AUTOSAR XML (schema 00050)
package /Diag_DidSwc
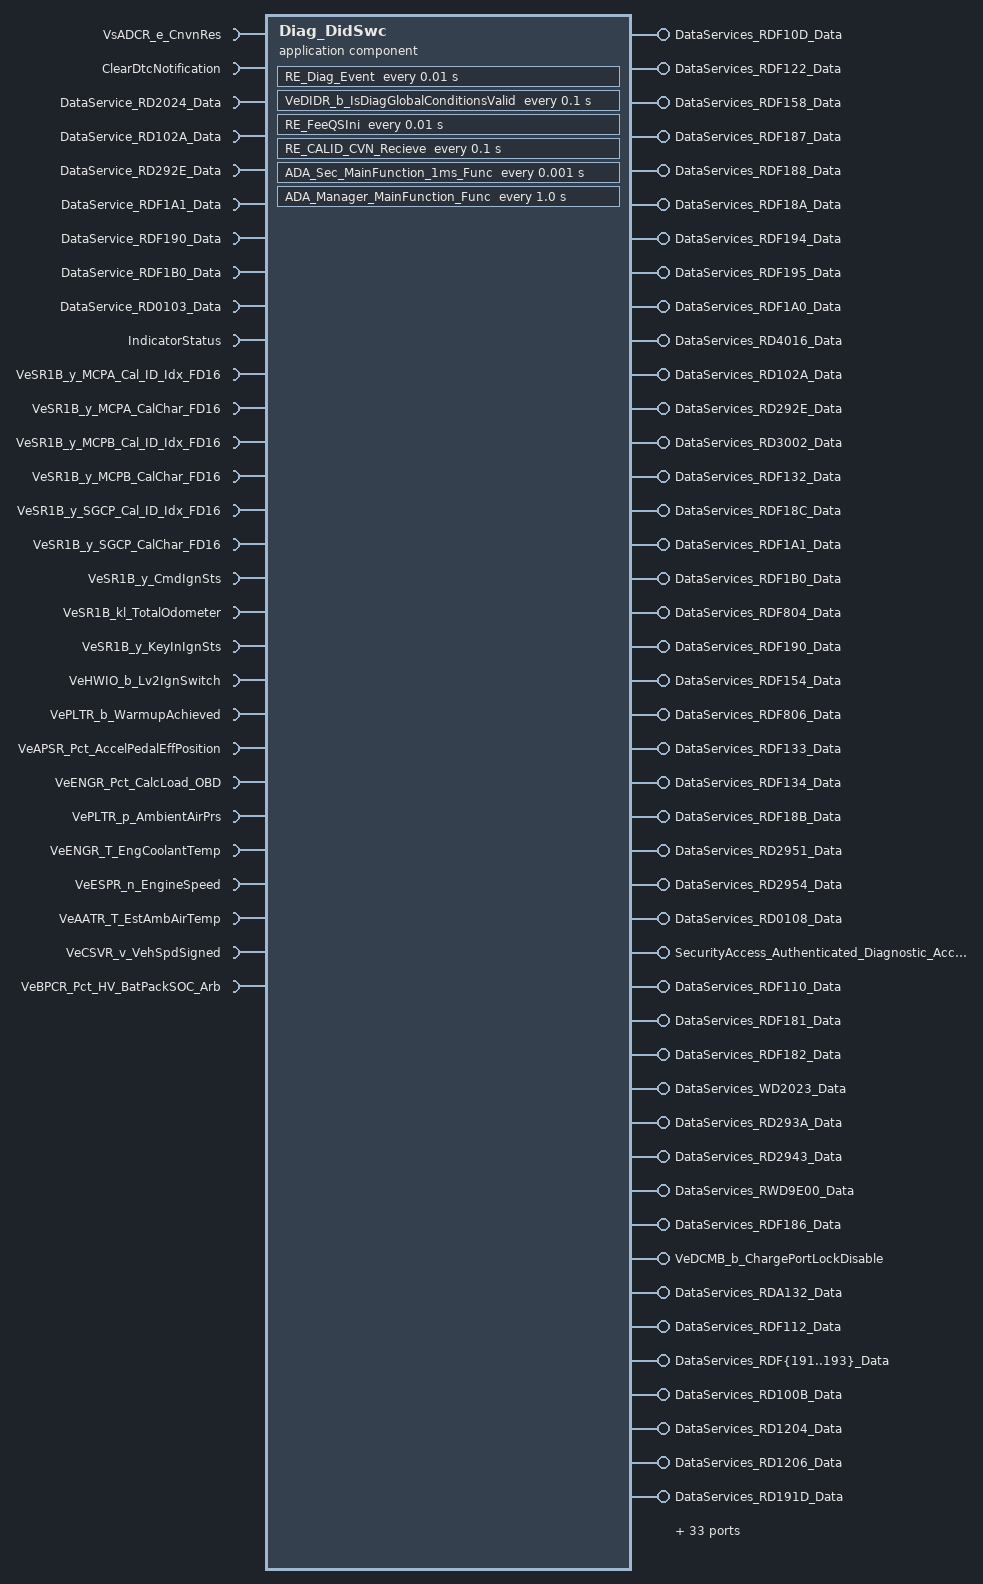
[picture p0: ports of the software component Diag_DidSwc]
  application sw component type Diag_DidSwc
    60 x provide port:
      DataServices_RDF10D_Data: provided-interface=DataServices_RDF10D_Data
      DataServices_RDF122_Data: provided-interface=DataServices_RDF122_Data
      DataServices_RDF158_Data: provided-interface=DataServices_RDF158_Data
      DataServices_RDF187_Data: provided-interface=DataServices_RDF187_Data
      DataServices_RDF188_Data: provided-interface=DataServices_RDF188_Data
      DataServices_RDF18A_Data: provided-interface=DataServices_RDF18A_Data
      DataServices_RDF194_Data: provided-interface=DataServices_RDF194_Data
      DataServices_RDF195_Data: provided-interface=DataServices_RDF195_Data
      DataServices_RDF1A0_Data: provided-interface=DataServices_RDF1A0_Data
      DataServices_RD4016_Data: provided-interface=DataServices_RD4016_Data
      DataServices_RD102A_Data: provided-interface=DataServices_RD102A_Data
      DataServices_RD292E_Data: provided-interface=DataServices_RD292E_Data
      DataServices_RD3002_Data: provided-interface=DataServices_RD3002_Data
      DataServices_RDF132_Data: provided-interface=DataServices_RDF132_Data
      DataServices_RDF18C_Data: provided-interface=DataServices_RDF18C_Data
      DataServices_RDF1A1_Data: provided-interface=DataServices_RDF1A1_Data
      DataServices_RDF1B0_Data: provided-interface=DataServices_RDF1B0_Data
      DataServices_RDF804_Data: provided-interface=DataServices_RDF804_Data
      DataServices_RDF190_Data: provided-interface=DataServices_RDF190_Data
      DataServices_RDF154_Data: provided-interface=DataServices_RDF154_Data
      DataServices_RDF806_Data: provided-interface=DataServices_RDF806_Data
      DataServices_RDF133_Data: provided-interface=DataServices_RDF133_Data
      DataServices_RDF134_Data: provided-interface=DataServices_RDF134_Data
      DataServices_RDF18B_Data: provided-interface=DataServices_RDF18B_Data
      DataServices_RD2951_Data: provided-interface=DataServices_RD2951_Data
      DataServices_RD2954_Data: provided-interface=DataServices_RD2954_Data
      DataServices_RD0108_Data: provided-interface=DataServices_RD0108_Data
      SecurityAccess_Authenticated_Diagnostic_Access_SecurityAccess_Even: provided-interface=SecurityAccess_Authenticated_Diagnostic_Access_SecurityAccess_Even
      DataServices_RDF110_Data: provided-interface=DataServices_RDF110_Data
      DataServices_RDF181_Data: provided-interface=DataServices_RDF181_Data
      DataServices_RDF182_Data: provided-interface=DataServices_RDF182_Data
      DataServices_WD2023_Data: provided-interface=DataServices_WD2023_Data
      DataServices_RD293A_Data: provided-interface=DataServices_RD293A_Data
      DataServices_RD2943_Data: provided-interface=DataServices_RD2943_Data
      DataServices_RWD9E00_Data: provided-interface=DataServices_RWD9E00_Data
      DataServices_RDF186_Data: provided-interface=DataServices_RDF186_Data
      VeDCMB_b_ChargePortLockDisable: provided-interface=VeDCMB_b_ChargePortLockDisable
      DataServices_RDA132_Data: provided-interface=DataServices_RDA132_Data
      DataServices_RDF112_Data: provided-interface=DataServices_RDF112_Data
      DataServices_RDF{191..193}_Data: provided-interface=DataServices_RDF{191..193}_Data
      DataServices_RD100B_Data: provided-interface=DataServices_RD100B_Data
      DataServices_RD1204_Data: provided-interface=DataServices_RD1204_Data
      DataServices_RD1206_Data: provided-interface=DataServices_RD1206_Data
      DataServices_RD191D_Data: provided-interface=DataServices_RD191D_Data
      DataServices_RD1921_Data: provided-interface=DataServices_RD1921_Data
      DataServices_RD2001_Data: provided-interface=DataServices_RD2001_Data
      DataServices_RD200A_Data: provided-interface=DataServices_RD200A_Data
      DataServices_RD200B_Data: provided-interface=DataServices_RD200B_Data
      DataServices_RD200C_Data: provided-interface=DataServices_RD200C_Data
      DataServices_RD6360_Data: provided-interface=DataServices_RD6360_Data
      DataServices_RDA186_Data: provided-interface=DataServices_RDA186_Data
      DataServices_RDF10B_Data: provided-interface=DataServices_RDF10B_Data
      DataServices_RDF155_Data: provided-interface=DataServices_RDF155_Data
      DataServices_RDF196_Data: provided-interface=DataServices_RDF196_Data
      DataServices_RD0701_Data: provided-interface=DataServices_RD0701_Data
      DataServices_RD1006_Data: provided-interface=DataServices_RD1006_Data
      DataServices_RD1008_Data: provided-interface=DataServices_RD1008_Data
      DataServices_RWD2945_Data: provided-interface=DataServices_RWD2945_Data
    require port VsADCR_e_CnvnRes: required-interface=VsADCR_e_CnvnRes
    5 x provide port:
      DataServices_RD0103_Data: provided-interface=DataServices_RD0103_Data
      DataServices_RWD0107_Data: provided-interface=DataServices_RWD0107_Data
      DataServices_RD0700_Data: provided-interface=DataServices_RD0700_Data
      DataServices_RD2010_Data: provided-interface=DataServices_RD2010_Data
      VeDIDR_b_IsDiagGlobalConditionsValid: provided-interface=VeDIDR_b_IsDiagGlobalConditionsValid
    4 x require port:
      ClearDtcNotification: required-interface=ClearDtcNotification
      DataService_RD2024_Data: required-interface=DataService_RD2024_Data
      DataService_RD102A_Data: required-interface=DataService_RD102A_Data
      DataService_RD292E_Data: required-interface=DataService_RD292E_Data
    provide port DataService_RD2023_Data: provided-interface=DataService_RD2023_Data
    4 x require port:
      DataService_RDF1A1_Data: required-interface=DataService_RDF1A1_Data
      DataService_RDF190_Data: required-interface=DataService_RDF190_Data
      DataService_RDF1B0_Data: required-interface=DataService_RDF1B0_Data
      DataService_RD0103_Data: required-interface=DataService_RD0103_Data
    provide port DataServices_RD2024_Data: provided-interface=DataServices_RD2024_Data
    11 x require port:
      IndicatorStatus: required-interface=IndicatorStatus
      VeSR1B_y_MCPA_Cal_ID_Idx_FD16: nonqueued-receiver-com-spec{data-element=Value, handle-never-received=true, init-value=0}, required-interface=VeSR1B_y_MCPA_Cal_ID_Idx_FD16
      VeSR1B_y_MCPA_CalChar_FD16: nonqueued-receiver-com-spec{data-element=Value, handle-never-received=true, init-value=0}, required-interface=VeSR1B_y_MCPA_CalChar_FD16
      VeSR1B_y_MCPB_Cal_ID_Idx_FD16: nonqueued-receiver-com-spec{data-element=Value, handle-never-received=true, init-value=0}, required-interface=VeSR1B_y_MCPB_Cal_ID_Idx_FD16
      VeSR1B_y_MCPB_CalChar_FD16: nonqueued-receiver-com-spec{data-element=Value, handle-never-received=true, init-value=0}, required-interface=VeSR1B_y_MCPB_CalChar_FD16
      VeSR1B_y_SGCP_Cal_ID_Idx_FD16: nonqueued-receiver-com-spec{data-element=Value, handle-never-received=true, init-value=0}, required-interface=VeSR1B_y_SGCP_Cal_ID_Idx_FD16
      VeSR1B_y_SGCP_CalChar_FD16: nonqueued-receiver-com-spec{data-element=Value, handle-never-received=true, init-value=0}, required-interface=VeSR1B_y_SGCP_CalChar_FD16
      VeSR1B_y_CmdIgnSts: nonqueued-receiver-com-spec{data-element=Value, handle-never-received=true, init-value=0}, required-interface=VeSR1B_y_CmdIgnSts
      VeSR1B_kl_TotalOdometer: nonqueued-receiver-com-spec{data-element=Value, handle-never-received=true, init-value=0}, required-interface=VeSR1B_kl_TotalOdometer
      VeSR1B_y_KeyInIgnSts: nonqueued-receiver-com-spec{data-element=Value, handle-never-received=true, init-value=0}, required-interface=VeSR1B_y_KeyInIgnSts
      VeHWIO_b_Lv2IgnSwitch: required-interface=VeHWIO_b_Lv2IgnSwitch
    4 x provide port:
      DataServices_RD1009_Data: provided-interface=DataServices_RD1009_Data
      DataServices_RD1004_Data: provided-interface=DataServices_RD1004_Data
      VeDIDR_b_PostCodeClrDiagDsbl: provided-interface=VeDIDR_b_PostCodeClrDiagDsbl
      VeDIDR_b_ClearTrackingInfoService04: provided-interface=VeDIDR_b_ClearTrackingInfoService04
    9 x require port:
      VePLTR_b_WarmupAchieved: required-interface=VePLTR_b_WarmupAchieved
      VeAPSR_Pct_AccelPedalEffPosition: required-interface=VeAPSR_Pct_AccelPedalEffPosition
      VeENGR_Pct_CalcLoad_OBD: required-interface=VeENGR_Pct_CalcLoad_OBD
      VePLTR_p_AmbientAirPrs: required-interface=VePLTR_p_AmbientAirPrs
      VeENGR_T_EngCoolantTemp: required-interface=VeENGR_T_EngCoolantTemp
      VeESPR_n_EngineSpeed: required-interface=VeESPR_n_EngineSpeed
      VeAATR_T_EstAmbAirTemp: required-interface=VeAATR_T_EstAmbAirTemp
      VeCSVR_v_VehSpdSigned: required-interface=VeCSVR_v_VehSpdSigned
      VeBPCR_Pct_HV_BatPackSOC_Arb: required-interface=VeBPCR_Pct_HV_BatPackSOC_Arb
    8 x provide port:
      VeDCMB_b_VePermanentFltCodesDsb: provided-interface=VeDCMB_b_VePermanentFltCodesDsb
      DataServices_RD1008_X_ECU_Life_Time_24: provided-interface=DataServices_RD1008_X_ECU_Life_Time_24
      DataServices_RD1009_X_ECU_Time_Since_Ignition_ON_24: provided-interface=DataServices_RD1009_X_ECU_Time_Since_Ignition_ON_24
      DataServices_RD2001_X_Odometer_24: provided-interface=DataServices_RD2001_X_Odometer_24
      DataServices_RD200A_X_Ignition_ON_Counter_24: provided-interface=DataServices_RD200A_X_Ignition_ON_Counter_24
      DataServices_RD1004_X_Battery_Voltage_24: provided-interface=DataServices_RD1004_X_Battery_Voltage_24
      DataServices_RD1006_X_Control_Module_Voltage_24: provided-interface=DataServices_RD1006_X_Control_Module_Voltage_24
      VeDIDR_b_DiagSystemDsbl: provided-interface=VeDIDR_b_DiagSystemDsbl
    behavior SwcInternalBehavior_0: data-type-mapping=[ADTtoIDTMapping, ADTtoIDTMapping, ADTtoIDTMapping]
      60 x operation invoked event:
        Op_DID_F122_Part_Number_24: start-on-event=RE_DID_F122, operation=DataServices_RDF122_Data.ReadData
        Op_DID_F188_SW_Num_24: start-on-event=RE_DID_F188, operation=DataServices_RDF188_Data.ReadData
        Op_DID_F158_Year_24: start-on-event=RE_DID_F158, operation=DataServices_RDF158_Data.ReadData
        Op_DID_F1A0_Part_Number_24: start-on-event=RE_DID_F1A0, operation=DataServices_RDF1A0_Data.ReadData
        Op_DID_F18A_Calib_Num_24: start-on-event=RE_DID_F18A, operation=DataServices_RDF18A_Data.ReadData
        Op_DID_F10D_Version_24: start-on-event=RE_DID_F10D, operation=DataServices_RDF10D_Data.ReadData
        Op_DID_F187_Part_Number_24: start-on-event=RE_DID_F187, operation=DataServices_RDF187_Data.ReadData
        Op_RD102A_ChckEOLCfgData: start-on-event=RE_RD102A_ChckEOLCfgData, operation=DataServices_RD102A_Data.ReadData
        Op_RD292E_PROXIWriteCounter: start-on-event=RE_RD292E_PROXIWriteCounter, operation=DataServices_RD292E_Data.ReadData
        Op_RD3002_OBDIIEnvDataFrzFrm: start-on-event=RE_RD3002_OBDIIEnvDataFrzFrm, operation=DataServices_RD3002_Data.ReadData
        Op_RDF132_EBOMECUPartNo: start-on-event=RE_RDF132_EBOMECUPartNo, operation=DataServices_RDF132_Data.ReadData
        Op_RDF18C_ECUSrlNo: start-on-event=RE_RDF18C_ECUSrlNo, operation=DataServices_RDF18C_Data.ReadData
        Op_RDF194_SupManuECUSWPrtNo: start-on-event=RE_RDF194_SupManuECUSWPrtNo, operation=DataServices_RDF194_Data.ReadData
        Op_RDF195_SupManfECUSWVerNo: start-on-event=RE_RDF195_SupManfECUSWVerNo, operation=DataServices_RDF195_Data.ReadData
        Op_RDF1A1_EOLCfgCode: start-on-event=RE_RDF1A1_EOLCfgCode, operation=DataServices_RDF1A1_Data.ReadData
        Op_RDF1B0_VINCurrent: start-on-event=RE_RDF1B0, operation=DataServices_RDF1B0_Data.ReadData
        Op_RDF804_CalibId: start-on-event=RE_RDF804, operation=DataServices_RDF804_Data.ReadData
        Op_RDF190_VINOriginal: start-on-event=RE_RDF190_VINOriginal, operation=DataServices_RDF190_Data.ReadData
        Op_RDF154_X_Hardware_Supplier_Identification_24: start-on-event=RE_RDF154_X_Hardware_Supplier_Identification_24, operation=DataServices_RDF154_Data.ReadData
        Op_RDF806_X_Number_of_Modules_24: start-on-event=RE_RDF806_X_Number_of_Modules_24, operation=DataServices_RDF806_Data.ReadData
        Op_RDF133_X_EBOM_Assembly_Part_Number_24: start-on-event=RE_RDF133_X_EBOM_Assembly_Part_Number_24, operation=DataServices_RDF133_Data.ReadData
        Op_RDF134_CODEP_assembly_part_number: start-on-event=RE_RDF134_CODEP_assembly_part_number, operation=DataServices_RDF134_Data.ReadData
        Op_RDF18B_X_FCA_ESLM_ECU_Software_Application_Number_24: start-on-event=RE_RDF18B_X_FCA_ESLM_ECU_Software_Application_Number_24, operation=DataServices_RDF18B_Data.ReadData
        Op_RD2951_Certificate_Store_UUID: start-on-event=RE_RD2951_Certificate_Store_UUID, operation=DataServices_RD2951_Data.ReadData
        Op_RD2954_Policy_Type_Logical_Block: start-on-event=RE_RD2954_Policy_Type_Logical_Block, operation=DataServices_RD2954_Data.ReadData
        Op_RD0108_X_Authenticated_Diagnostics_Active_Roles_24: start-on-event=RE_RD0108_X_Authenticated_Diagnostics_Active_Roles_24, operation=DataServices_RD0108_Data.ReadData
        Op_Authenticated_Diagnostic_Access_SecurityAccess_Even_GetSeed: start-on-event=RE_Authenticated_Diagnostic_Access_SecurityAccess_Even_GetSeed, operation=SecurityAccess_Authenticated_Diagnostic_Access_SecurityAccess_Even.GetSeed
        Op_Authenticated_Diagnostic_Access_SecurityAccess_EvenCmprKey: start-on-event=RE_Authenticated_Diagnostic_Access_SecurityAccess_EvenCmprKey, operation=SecurityAccess_Authenticated_Diagnostic_Access_SecurityAccess_Even.CompareKey
        Op_RDF110_X_Diagnostic_Variant_24: start-on-event=RE_RDF110_X_Diagnostic_Variant_24, operation=DataServices_RDF110_Data.ReadData
        Op_RDF181_App_SW_Identification: start-on-event=RE_RDF181_App_SW_Identification, operation=DataServices_RDF181_Data.ReadData
        Op_RDF182_App_Data_Identification: start-on-event=RE_RDF182_App_Data_Identification, operation=DataServices_RDF182_Data.ReadData
        Op_WD2023_PROXIData: start-on-event=RE_WD2023_PROXIData, operation=DataServices_WD2023_Data.WriteData
        Op_RD293A_Data: start-on-event=RE_RD293A_Data, operation=DataServices_RD293A_Data.ReadData
        Op_RD2943_Data: start-on-event=RE_RD2943_Data, operation=DataServices_RD2943_Data.ReadData
        Op_RDF186_Data: start-on-event=RE_RDF186_Data, operation=DataServices_RDF186_Data.ReadData
        Op_RWD9E00_Read: start-on-event=RE_RW9E00_Data_Read, operation=DataServices_RWD9E00_Data.ReadData
        Op_RWD9E00_Write: start-on-event=RE_RD9E00_Data_Write, operation=DataServices_RWD9E00_Data.WriteData
        Op_RDA132_Data: start-on-event=RE_RDA132_Data, operation=DataServices_RDA132_Data.ReadData
        Op_RDF112_Data: start-on-event=RE_RDF112_Data, operation=DataServices_RDF112_Data.ReadData
        Op_RDF192_Data: start-on-event=RE_RDF192_Data, operation=DataServices_RDF192_Data.ReadData
        Op_RDF191_Data: start-on-event=RE_RDF191_Data, operation=DataServices_RDF191_Data.ReadData
        Op_RDF193_Data: start-on-event=RE_RDF193_Data, operation=DataServices_RDF193_Data.ReadData
        Op_RD100B_Data: start-on-event=RE_RD100B_Data, operation=DataServices_RD100B_Data.ReadData
        Op_RD1204_Data: start-on-event=RE_RD1204_Data, operation=DataServices_RD1204_Data.ReadData
        Op_RDF155_Data: start-on-event=RE_RDF155_Data, operation=DataServices_RDF155_Data.ReadData
        Op_RD200C_Data: start-on-event=RE_RD200C_Data, operation=DataServices_RD200C_Data.ReadData
        Op_RD2001_Data: start-on-event=RE_RD2001_Data, operation=DataServices_RD2001_Data.ReadData
        Op_RDF10B_Data: start-on-event=RE_RDF10B_Data, operation=DataServices_RDF10B_Data.ReadData
        Op_RD200A_Data: start-on-event=RE_RD200A_Data, operation=DataServices_RD200A_Data.ReadData
        Op_RDF196_Data: start-on-event=RE_RDF196_Data, operation=DataServices_RDF196_Data.ReadData
        Op_RDA186_Data: start-on-event=RE_RDA186_Data, operation=DataServices_RDA186_Data.ReadData
        Op_RD191D_Data: start-on-event=RE_RD191D_Data, operation=DataServices_RD191D_Data.ReadData
        Op_RD6360_Data: start-on-event=RE_RD6360_Data, operation=DataServices_RD6360_Data.ReadData
        Op_RD200B_Data: start-on-event=RE_RD200B_Data, operation=DataServices_RD200B_Data.ReadData
        Op_RD1921_Data: start-on-event=RE_RD1921_Data, operation=DataServices_RD1921_Data.ReadData
        Op_RD1006_Data: start-on-event=RE_RD1006_Data, operation=DataServices_RD1006_Data.ReadData
        Op_RD1008_Data: start-on-event=RE_RD1008_Data, operation=DataServices_RD1008_Data.ReadData
        Op_RWD2945_ReadData: start-on-event=RE_RWD2945_ReadData, operation=DataServices_RWD2945_Data.ReadData
        Op_RWD2945_WriteData: start-on-event=RE_RWD2945_WriteData, operation=DataServices_RWD2945_Data.WriteData
        Op_RD0701_Data: start-on-event=RE_RD0701_Data, operation=DataServices_RD0701_Data.ReadData
      timing event TE_Diag_Event: start-on-event=RE_Diag_Event, period=0.01
      5 x operation invoked event:
        Op_RD0103_Data: start-on-event=PPort_RD0103_Data, operation=DataServices_RD0103_Data.ReadData
        Op_RD0107_Data: start-on-event=PPort_RD0107_Data, operation=DataServices_RWD0107_Data.ReadData
        Op_RWD0107_Data: start-on-event=PPort_RWD0107_Data, operation=DataServices_RWD0107_Data.WriteData
        PPort_RD0700_Data: start-on-event=RE_RD0700_Data, operation=DataServices_RD0700_Data.ReadData
        Op_RD2010_Data: start-on-event=PPort_RD2010_Data, operation=DataServices_RD2010_Data.ReadData
      timing event TE_VeDIDR_b_IsDiagGlobalConditionsValid: start-on-event=VeDIDR_b_IsDiagGlobalConditionsValid, period=0.1
      operation invoked event Op_RD2024_Data: start-on-event=RE_RD2024_Data, operation=DataServices_RD2024_Data.ReadData
      timing event TE_FeeQSIni: start-on-event=RE_FeeQSIni, period=0.01
      operation invoked event Op_RD1206_Data: start-on-event=RE_RD1206_Data, operation=DataServices_RD1206_Data.ReadData
      timing event TE_CALID_CVN_Recieve: start-on-event=RE_CALID_CVN_Recieve, period=0.1
      operation invoked event Op_RD1009_Data: start-on-event=RE_RD1009_Data, operation=DataServices_RD1009_Data.ReadData
      operation invoked event Op_RD1004_Data: start-on-event=RE_RD1004_Data, operation=DataServices_RD1004_Data.ReadData
      timing event TE_ADA_1ms: start-on-event=ADA_Sec_MainFunction_1ms_Func, period=0.001
      timing event TE_ADA_1000ms: start-on-event=ADA_Manager_MainFunction_Func, period=1.0
      6 x operation invoked event:
        Op_Dem_RD200A: start-on-event=RE_Dem_RD200A, operation=DataServices_RD200A_X_Ignition_ON_Counter_24.ReadData
        Op_Dem_RD1009: start-on-event=RE_Dem_RD1009, operation=DataServices_RD1009_X_ECU_Time_Since_Ignition_ON_24.ReadData
        Op_Dem_RD2001: start-on-event=RE_Dem_RD2001, operation=DataServices_RD2001_X_Odometer_24.ReadData
        Op_Dem_RD1008: start-on-event=RE_Dem_RD1008, operation=DataServices_RD1008_X_ECU_Life_Time_24.ReadData
        Op_Dem_RD1004: start-on-event=RE_Dem_RD1004, operation=DataServices_RD1004_X_Battery_Voltage_24.ReadData
        Op_Dem_RD1006: start-on-event=RE_Dem_RD1006, operation=DataServices_RD1006_X_Control_Module_Voltage_24.ReadData
      85 x runnable:
        RE_DID_F10D: symbol=RE_DID_F10D_func
        RE_DID_F122: symbol=RE_DID_F122_func
        RE_DID_F158: symbol=RE_DID_F158_Year_func
        RE_DID_F187: symbol=RE_DID_F187_func
        RE_DID_F188: symbol=RE_DID_F188_func
        RE_DID_F18A: symbol=RE_DID_F18A_func
        RE_DID_F1A0: symbol=RE_DID_F1A0_func
        RE_RDF804: symbol=RE_RDF804_func
        RE_RDF1B0: symbol=RE_RDF1B0_func
          data-receive-point-by-arguments:
            access DRPA_RDF1B0: accessed-variable=DataService_RDF1B0_Data.RDF1B0
        RE_RDF1A1_EOLCfgCode: symbol=RE_RDF1A1_EOLCfgCode_func
          data-receive-point-by-arguments:
            access DRPA_RDF1A1_Data_0: accessed-variable=DataService_RDF1A1_Data.RDF1A1_Data
        RE_RDF18C_ECUSrlNo: symbol=RE_RDF18C_ECUSrlNo_func
        RE_RDF132_EBOMECUPartNo: symbol=RE_RDF132_EBOMECUPartNo_func
        RE_RD4016_ElecACCmprsrRdFltSts: symbol=RE_RD4016_ElecACCmprsrRdFltSts_func
        RE_RD3002_OBDIIEnvDataFrzFrm: symbol=RE_RD3002_OBDIIEnvDataFrzFrm_func
          data-receive-point-by-arguments:
            9 x access:
              DataReceivePointByArguments_VariableAccess_0: accessed-variable=VePLTR_b_WarmupAchieved.Value
              DataReceivePointByArguments_VariableAccess_1: accessed-variable=VeAPSR_Pct_AccelPedalEffPosition.Value
              DataReceivePointByArguments_VariableAccess_2: accessed-variable=VeENGR_Pct_CalcLoad_OBD.Value
              DataReceivePointByArguments_VariableAccess_3: accessed-variable=VePLTR_p_AmbientAirPrs.Value
              DataReceivePointByArguments_VariableAccess_4: accessed-variable=VeENGR_T_EngCoolantTemp.Value
              DataReceivePointByArguments_VariableAccess_5: accessed-variable=VeESPR_n_EngineSpeed.Value
              DataReceivePointByArguments_VariableAccess_6: accessed-variable=VeAATR_T_EstAmbAirTemp.Value
              DataReceivePointByArguments_VariableAccess_7: accessed-variable=VeCSVR_v_VehSpdSigned.Value
              DataReceivePointByArguments_VariableAccess_8: accessed-variable=VeBPCR_Pct_HV_BatPackSOC_Arb.Value
        RE_RD292E_PROXIWriteCounter: symbol=RE_RD292E_PROXIWriteCounter_func
          data-receive-point-by-arguments:
            access DRPA_RD292E_Data_0: accessed-variable=DataService_RD292E_Data.RD292E_Data
        RE_RD102A_ChckEOLCfgData: symbol=RE_RD102A_ChckEOLCfgData_func
          data-receive-point-by-arguments:
            access DRPA_RD102A_Data_0: accessed-variable=DataService_RD102A_Data.RD102A_Data
        RE_RDF194_SupManuECUSWPrtNo: symbol=RE_RDF194_SupManuECUSWPrtNo_func
        RE_RDF195_SupManfECUSWVerNo: symbol=RE_RDF195_SupManfECUSWVerNo_func
        RE_RDF190_VINOriginal: symbol=RE_RDF190_VINOriginal_func
          data-receive-point-by-arguments:
            access DRPA_RDF190: accessed-variable=DataService_RDF190_Data.RWDF190
        RE_RDF154_X_Hardware_Supplier_Identification_24: symbol=RE_RDF154_X_Hardware_Supplier_Identification_24_func
        RE_RDF806_X_Number_of_Modules_24: symbol=RE_RDF806_X_Number_of_Modules_24_func
        RE_RDF133_X_EBOM_Assembly_Part_Number_24: symbol=RE_RDF133_X_EBOM_Assembly_Part_Number_24_func
        RE_RDF134_CODEP_assembly_part_number: symbol=RE_RDF134_CODEP_assembly_part_number_func
        RE_RDF18B_X_FCA_ESLM_ECU_Software_Application_Number_24: symbol=RE_RDF18B_X_FCA_ESLM_ECU_Software_Application_Number_24_func
        RE_RD2951_Certificate_Store_UUID: symbol=RE_RD2951_Certificate_Store_UUID_func
        RE_RD2954_Policy_Type_Logical_Block: symbol=RE_RD2954_Policy_Type_Logical_Block_func
        RE_RD0108_X_Authenticated_Diagnostics_Active_Roles_24: symbol=RE_RD0108_X_Authenticated_Diagnostics_Active_Roles_24_func
        RE_Authenticated_Diagnostic_Access_SecurityAcces_GetSeed: symbol=RE_Authenticated_Diagnostic_Access_SecurityAcces_GetSeed_Func
        RE_Authenticated_Diagnostic_Access_SecurityAcces_CmprKey: symbol=RE_Authenticated_Diagnostic_Access_SecurityAcces_CmprKey_Func
        RE_Authenticated_Diagnostic_Access_SecurityAccess_EvenCmprKey: symbol=RE_Authenticated_Diagnostic_Access_SecurityAccess_Even_CmprKey_func
        RE_Authenticated_Diagnostic_Access_SecurityAccess_Even_GetSeed: symbol=RE_Authenticated_Diagnostic_Access_SecurityAccess_Even_GetSeed_func
        RE_RDF110_X_Diagnostic_Variant_24: symbol=RE_RDF110_X_Diagnostic_Variant_24_func
        RE_RDF181_App_SW_Identification: symbol=RE_RDF181_App_SW_Identification_func
        RE_RDF182_App_Data_Identification: symbol=RE_RDF182_App_Data_Identification_func
        RE_WD2023_PROXIData: symbol=RE_WD2023_PROXIData_func
          data-send-points:
            access DSP_RD2023_Data: accessed-variable=DataService_RD2023_Data.RD2023_Data
        RE_RD293A_Data: symbol=RE_RD293A_Data_func
        RE_RD2943_Data: symbol=RE_RD2943_Data_func
        RE_RDF1AA_Data: symbol=RE_RDF1AA_Data_func
        RE_RD9E00_Data_Write: symbol=RE_RD9E00_Data_Write_func
        RE_RW9E00_Data_Read: symbol=RE_RD9E00_Data_Read_func
          data-send-points:
            access DSP_VeDCMB_b_VePermanentFltCodesDsb_0: accessed-variable=VeDCMB_b_VePermanentFltCodesDsb.VeDCMB_b_VePermanentFltCodesDsb
            access DSP_VeDCMB_b_ChargePortLockDisable_0: accessed-variable=VeDCMB_b_ChargePortLockDisable.VeDCMB_b_ChargePortLockDisable
        RE_RDF186_Data: symbol=RE_RDF186_Data_func
        RE_RDA132_Data
        RE_RDF112_Data: symbol=RE_RDF112_ECUIdHWPartNo_func
        RE_RDF191_Data: symbol=RE_RDF191_ECUHWPartNo_func
        RE_RDF192_Data: symbol=RE_RDF192_SupManfECUPartNofunc
        RE_RDF193_Data: symbol=RE_RDF193_SupManECUHWVerno_func
        RE_RD100B_Data
        RE_RD1204_Data
          data-receive-point-by-arguments:
            access DataReceivePointByArguments_VariableAccess_0: accessed-variable=VsADCR_e_CnvnRes.VsADCR_e_CnvnRes
        RE_RD1206_Data
          data-receive-point-by-arguments:
            access DataReceivePointByArguments_VariableAccess_0: accessed-variable=VsADCR_e_CnvnRes.VsADCR_e_CnvnRes
        RE_RD191D_Data
        RE_RD1921_Data
          data-receive-point-by-arguments:
            access DataReceivePointByArguments_VariableAccess_0: accessed-variable=VeSR1B_y_CmdIgnSts.Value
            access DRP_VeSR1B_y_KeyInIgnSts: accessed-variable=VeSR1B_y_KeyInIgnSts.Value
        RE_RD2001_Data
          data-receive-point-by-arguments:
            access DataReceivePointByArguments_VariableAccess_0: accessed-variable=VeSR1B_kl_TotalOdometer.Value
        RE_RD200A_Data
        RE_RD200B_Data
        RE_RD200C_Data
        RE_RD6360_Data
        RE_RDA186_Data
        RE_RDF10B_Data
        RE_RDF155_Data
        RE_RDF196_Data
        RE_RD0701_Data
        RE_RD1006_Data
          data-receive-point-by-arguments:
            access DataReceivePointByArguments_VariableAccess_0: accessed-variable=VsADCR_e_CnvnRes.VsADCR_e_CnvnRes
        RE_RD1008_Data
        RE_RWD2945_ReadData
        RE_RWD2945_WriteData
        RE_Diag_Event: symbol=RE_Diag_Event_func
        RE_RD0700_Data: symbol=RE_RD0700_Data_func
        PPort_RWD0107_Data: symbol=PPort_RWD0107_Data_func
        PPort_RD0107_Data: symbol=PPort_RD0107_Data_func
        PPort_RD0103_Data: symbol=PPort_RD0103_Data_func
          data-receive-point-by-arguments:
            access DRPA_RD0103: accessed-variable=DataService_RD0103_Data.RD0103
        PPort_RD2010_Data: symbol=PPort_RD2010_Data_finc
        VeDIDR_b_IsDiagGlobalConditionsValid
          data-receive-point-by-arguments:
            access DRPA_VsADCR_e_CnvnRes_0: accessed-variable=VsADCR_e_CnvnRes.VsADCR_e_CnvnRes
          data-send-points:
            access DSP_VeDIDR_b_IsDiagGlobalConditionsValid: accessed-variable=VeDIDR_b_IsDiagGlobalConditionsValid.VeDIDR_b_IsDiagGlobalConditionsValid
            access DSP_VeDIDR_b_ClearTrackingInfoService04_0: accessed-variable=VeDIDR_b_ClearTrackingInfoService04.VeDIDR_b_ClearTrackingInfoService04
            access DSP_VeDIDR_b_PostCodeClrDiagDsbl_0: accessed-variable=VeDIDR_b_PostCodeClrDiagDsbl.VeDIDR_b_PostCodeClrDiagDsbl
          sync call SynchronousServerCallPoint_0: operation=ClearDtcNotification.ClearDtcNotification
        RE_RD2024_Data: symbol=RE_RD2024_Data_func
          data-receive-point-by-arguments:
            access DRPA_RD2024_0: accessed-variable=DataService_RD2024_Data.RD2024
        RE_FeeQSIni: symbol=RE_FeeQSIni_func
        RE_CALID_CVN_Recieve
          data-receive-point-by-arguments:
            6 x access:
              DataReceivePointByArguments_VariableAccess_0: accessed-variable=VeSR1B_y_MCPA_Cal_ID_Idx_FD16.Value
              DataReceivePointByArguments_VariableAccess_1: accessed-variable=VeSR1B_y_MCPA_CalChar_FD16.Value
              DataReceivePointByArguments_VariableAccess_2: accessed-variable=VeSR1B_y_MCPB_Cal_ID_Idx_FD16.Value
              DataReceivePointByArguments_VariableAccess_2_Copy: accessed-variable=VeSR1B_y_MCPB_CalChar_FD16.Value
              DataReceivePointByArguments_VariableAccess_3: accessed-variable=VeSR1B_y_SGCP_Cal_ID_Idx_FD16.Value
              DataReceivePointByArguments_VariableAccess_4: accessed-variable=VeSR1B_y_SGCP_CalChar_FD16.Value
        RE_RD1009_Data: symbol=RE_RD1009_Data_func
        RE_RD1004_Data: symbol=RE_RD1004_Data_func
        ADA_Sec_MainFunction_1ms_Func: symbol=ADA_Sec_MainFunction_1ms
        ADA_Manager_MainFunction_Func: symbol=ADA_Manager_MainFunction_1000ms
        RE_Dem_RD1008: symbol=RE_Dem_RD1008_func
        RE_Dem_RD1009: symbol=RE_Dem_RD1009_func
        RE_Dem_RD2001: symbol=RE_Dem_RD2001_func
        RE_Dem_RD200A: symbol=RE_Dem_RD200A_func
        RE_Dem_RD1006: symbol=RE_Dem_RD1006_func
        RE_Dem_RD1004: symbol=RE_Dem_RD1004_func
      shared-parameters:
        21 x parameter data prototype:
          KeDFIR_UDS_Protocol_ver: sw-calibration-access=READ-ONLY, type=Dcm_DataArrayTypeUint8_RDF10D_DataType, init-value=DID_F10D:[KeDFIR_UDS_Protocol_ver:147, KeDFIR_ECU_FlashProg_Req_Ver:51, KeDFIR_UDS_SDD_Ver:69, KeDFIR_STD_DIAG_Req_Ver:84]
          KeBSWR_y_F18B_ManufacturerECUSoftwareApplNumber: sw-calibration-access=READ-ONLY, type=Dcm_DataArrayTypeUint8_RDF18B_DataType, init-value=KeBSWR_y_F18B_ManufacturerECUSoftwareApplNumber:10 x NumericalValueSpecification_0:32
          KeBSWR_y_F18A_ManufacturerECUSoftwareCalNumber: sw-calibration-access=READ-ONLY, type=Dcm_DataArrayTypeUint8_RDF18A_DataType, init-value=KeBSWR_y_F18A_ManufacturerECUSoftwareCalNumber:10 x NumericalValueSpecification_0:32
          KeBSWR_y_F188_ManufacturerECUSoftwareNumber: sw-calibration-access=READ-ONLY, type=Dcm_DataArrayTypeUint8_RDF188_DataType, init-value=KeBSWR_y_F188_ManufacturerECUSoftwareNumber:11 x NumericalValueSpecification_0:32
          KeBSWR_y_F134_CODEPPartNumber:
            sw-calibration-access=READ-ONLY
            type=Dcm_DataArrayTypeUint8_RDF134_DataType
            init-value=KeBSWR_y_F134_CODEPPartNumber:[NumericalValueSpecification_0:51, NumericalValueSpecification_0:52, NumericalValueSpecification_0:53, NumericalValueSpecification_0:54, NumericalValueSpecification_0:55, NumericalValueSpecification_0:56, NumericalValueSpecification_0:57, NumericalValueSpecification_0:58, NumericalValueSpecification_0:59, NumericalValueSpecification_0:60, NumericalValueSpecification_0:61]
          KeBSWR_y_F133_EBOMPartNumber:
            sw-calibration-access=READ-ONLY
            type=Dcm_DataArrayTypeUint8_RDF133_DataType
            init-value=KeBSWR_y_F133_EBOMPartNumber:[NumericalValueSpecification_0:60, NumericalValueSpecification_0:61, NumericalValueSpecification_0:62, NumericalValueSpecification_0:63, NumericalValueSpecification_0:50, NumericalValueSpecification_0:65, NumericalValueSpecification_0:66, NumericalValueSpecification_0:67, NumericalValueSpecification_0:68, NumericalValueSpecification_0:69]
          KeBSWR_y_ChryslerSWPartNo_CodeBlk:
            sw-calibration-access=READ-ONLY
            type=Dcm_DataArrayTypeUint8_RDF122_DataType
            init-value=KeBSWR_y_ChryslerSWPartNo_CodeBlk:[NumericalValueSpecification_0:21, NumericalValueSpecification_0:22, NumericalValueSpecification_0:23, NumericalValueSpecification_0:24, NumericalValueSpecification_0:25, NumericalValueSpecification_0:26, NumericalValueSpecification_0:27, NumericalValueSpecification_0:28, NumericalValueSpecification_0:29, NumericalValueSpecification_0:30]
          KeBSWR_y_ECU_SparePartNumber: sw-calibration-access=READ-ONLY, type=Dcm_DataArrayTypeUint8_RDF187_DataType, init-value=KeBSWR_y_ECU_SparePartNumber:11 x NumericalValueSpecification_0:32
          KeBSWR_y_SysSuppECU_SWNum: sw-calibration-access=READ-ONLY, type=Dcm_DataArrayTypeUint8_RDF194_DataType, init-value=KeBSWR_y_SysSuppECU_SWNum:11 x NumericalValueSpecification_0:32
          KeBSWR_y_SysSuppECU_SWVerNum: sw-calibration-access=READ-ONLY, type=Dcm_DataArrayTypeUint8_RDF195_DataType, init-value=KeBSWR_y_SysSuppECU_SWVerNum:[NumericalValueSpecification_0:32, NumericalValueSpecification_0:32]
          KeBSWR_y_DiagnosticVersion: sw-calibration-access=READ-ONLY, type=Dcm_DataArrayTypeUint8_RDF110_DataType, init-value=KeBSWR_y_DiagnosticVersion:[NumericalValueSpecification_0:00, NumericalValueSpecification_0:00, NumericalValueSpecification_0:00, NumericalValueSpecification_0:00]
          KeBSWR_y_ApplSW_ID:
            sw-calibration-access=READ-ONLY
            type=Dcm_DataArrayTypeUint8_RDF181_DataType
            init-value=KeBSWR_y_ApplSW_ID:[NumericalValueSpecification_0:02, NumericalValueSpecification_0:98, NumericalValueSpecification_0:52, NumericalValueSpecification_0:50, NumericalValueSpecification_0:51, NumericalValueSpecification_0:52, NumericalValueSpecification_0:53, NumericalValueSpecification_0:54, NumericalValueSpecification_0:55, NumericalValueSpecification_0:56, NumericalValueSpecification_0:57, NumericalValueSpecification_0:65, NumericalValueSpecification_0:66, NumericalValueSpecification_0:67, NumericalValueSpecification_0:98, NumericalValueSpecification_0:52, NumericalValueSpecification_0:50, NumericalValueSpecification_0:51, NumericalValueSpecification_0:52, NumericalValueSpecification_0:53, NumericalValueSpecification_0:54, NumericalValueSpecification_0:55, NumericalValueSpecification_0:56, NumericalValueSpecification_0:57, NumericalValueSpecification_0:65, NumericalValueSpecification_0:66, NumericalValueSpecification_0:67]
          KeBSWR_y_ApplData_ID:
            sw-calibration-access=READ-ONLY
            type=Dcm_DataArrayTypeUint8_RDF182_DataType
            init-value=KeBSWR_y_ApplData_ID:[NumericalValueSpecification_0:04, NumericalValueSpecification_0:98, NumericalValueSpecification_0:52, NumericalValueSpecification_0:50, NumericalValueSpecification_0:51, NumericalValueSpecification_0:52, NumericalValueSpecification_0:53, NumericalValueSpecification_0:54, NumericalValueSpecification_0:55, NumericalValueSpecification_0:56, NumericalValueSpecification_0:57, NumericalValueSpecification_0:65, NumericalValueSpecification_0:66, NumericalValueSpecification_0:67, NumericalValueSpecification_0:98, NumericalValueSpecification_0:52, NumericalValueSpecification_0:50, NumericalValueSpecification_0:51, NumericalValueSpecification_0:52, NumericalValueSpecification_0:53, NumericalValueSpecification_0:54, NumericalValueSpecification_0:55, NumericalValueSpecification_0:56, NumericalValueSpecification_0:57, NumericalValueSpecification_0:65, NumericalValueSpecification_0:66, NumericalValueSpecification_0:67, NumericalValueSpecification_0:98, NumericalValueSpecification_0:52, NumericalValueSpecification_0:50, NumericalValueSpecification_0:51, NumericalValueSpecification_0:52, NumericalValueSpecification_0:53, NumericalValueSpecification_0:54, NumericalValueSpecification_0:55, NumericalValueSpecification_0:56, NumericalValueSpecification_0:57, NumericalValueSpecification_0:65, NumericalValueSpecification_0:66, NumericalValueSpecification_0:67, NumericalValueSpecification_0:98, NumericalValueSpecification_0:52, NumericalValueSpecification_0:50, NumericalValueSpecification_0:51, NumericalValueSpecification_0:52, NumericalValueSpecification_0:53, NumericalValueSpecification_0:54, NumericalValueSpecification_0:55, NumericalValueSpecification_0:56, NumericalValueSpecification_0:57, NumericalValueSpecification_0:65, NumericalValueSpecification_0:66, NumericalValueSpecification_0:67]
          CalBlckHeader: type=IDTR_LogicalBlock, init-value={short-label=Calblockheader, fields=[EcuPartNumber:[ECU_PRTNUM_BYTE0:48, ECU_PRTNUM_BYTE1:49, ECU_PRTNUM_BYTE2:48, ECU_PRTNUM_BYTE3:49, ECU_PRTNUM_BYTE4:50, ECU_PRTNUM_BYTE5:51, ECU_PRTNUM_BYTE6:52, ECU_PRTNUM_BYTE7:53, ECU_PRTNUM_BYTE8:66, ECU_PRTNUM_BYTE9:67, ECU_PRTNUM_BYTE10:48], SwPartNumber:[SW_PRTNUM_1_BYTE0:32, SW_PRTNUM_1_BYTE1:32, SW_PRTNUM_1_BYTE2:32, SW_PRTNUM_1_BYTE3:32, SW_PRTNUM_1_BYTE4:32, SW_PRTNUM_1_BYTE5:32, SW_PRTNUM_1_BYTE6:32, SW_PRTNUM_1_BYTE7:32, SW_PRTNUM_1_BYTE8:32, SW_PRTNUM_1_BYTE9:32], SupplierID:[SUPPLIER_ID_BYTE0:01, SUPPLIER_ID_BYTE1:11]]}
          KeBSWR_y_ExhaustRegulationNum: sw-calibration-access=READ-ONLY, type=Dcm_DataArrayTypeUint8_RDF196_DataType, init-value=KeBSWR_y_ExhaustRegulationNum:[NumericalValueSpecification_0:48, NumericalValueSpecification_0:49, NumericalValueSpecification_0:50, NumericalValueSpecification_0:51, NumericalValueSpecification_0:52, NumericalValueSpecification_0:53]
          KeBSWR_t_IgnCounterTmrThreshold: sw-calibration-access=READ-ONLY, type=Dcm_DataArrayTypeUint8_RD200A_DataType, init-value=KeBSWR_t_IgnCounterTmrThreshold:[NumericalValueSpecification_0:48]
          KeBSWR_t_PwrLatchTime: sw-calibration-access=READ-ONLY, type=Dcm_DataArrayTypeUint8_RD191D_DataType, init-value=KeBSWR_t_PwrLatchTime:[NumericalValueSpecification_0:51, NumericalValueSpecification_0:52]
          KeBSWR_b_ProgCondPwMdChk_Enable: sw-calibration-access=READ-ONLY, type=Dcm_DataArrayTypeUint8_IOCD002_DataType, init-value=KeBSWR_b_ProgCondPwMdChk_Enable:[NumericalValueSpecification_0:51]
          KeDFIR_mt_CodeClrDsblTmr: sw-calibration-access=READ-ONLY, unit=ms, type=uint8, init-value=NumericalValueSpecification_0:500
          KeHWIO_BattVolt_OperLimLow: sw-calibration-access=READ-ONLY, type=uint8, init-value=NumericalValueSpecification_0:8
          KeHWIO_BattVolt_OperLimHigh: sw-calibration-access=READ-ONLY, type=uint8, init-value=NumericalValueSpecification_0:16
